# LPC18xx register map
File version: 18
Registers are 32-bit, read-write, reset 0x0 unless marked. A register's access mark holds for its fields unless they carry their own. Offsets are from the block's base; [hi:lo] are bit positions; {n}, {i} and the like mark numbered series.

## EVENTROUTER — Product name title=UM10430 Chapter title=LPC18xx Event router Modification date=1/20/2011 Major revision=0 Minor revision=7
Base 0x40044000
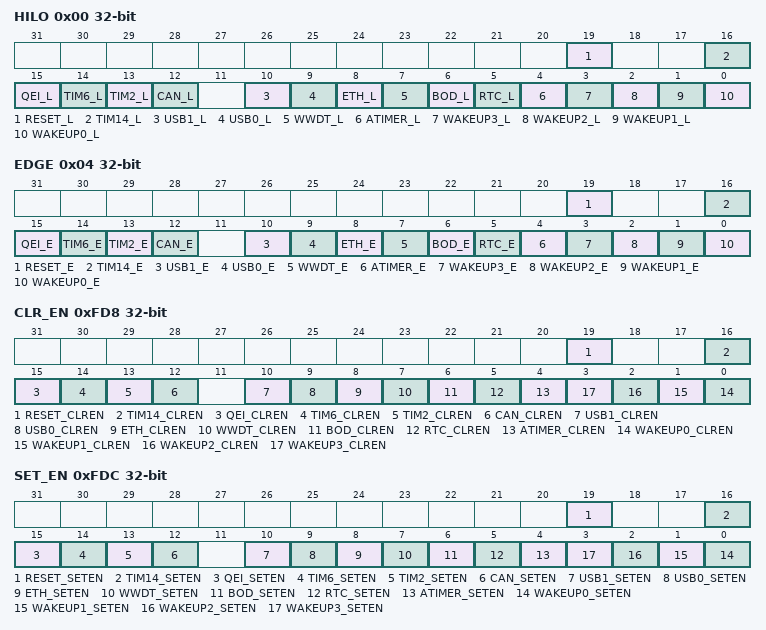
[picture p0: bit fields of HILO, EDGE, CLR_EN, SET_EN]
0x00 HILO — Level configuration register
  [19] RESET_L — Level detect mode for RESET event.
    0=DETECT_LOW_LEVEL_IF_ (Detect LOW level if bit 17 in the EDGE register is 0. Detect falling edge if bit 17 in the EDGE register is 1.); 1=DETECT_HIGH_LEVEL_IF (Detect HIGH level if bit 17 in the EDGE register is 0. Detect rising edge if bit 17 in the EDGE register is 1.)
  [16] TIM14_L — Level detect mode for combined timer output 14 event.
    0=DETECT_LOW_LEVEL_IF_ (Detect LOW level if bit 16 in the EDGE register is 0. Detect falling edge if bit 16 in the EDGE register is 1.); 1=DETECT_HIGH_LEVEL_IF (Detect HIGH level if bit 16 in the EDGE register is 0. Detect rising edge if bit 16 in the EDGE register is 1.)
  [15] QEI_L — Level detect mode for QEI event.
    0=DETECT_LOW_LEVEL_IF_ (Detect LOW level if bit 15 in the EDGE register is 0. Detect falling edge if bit 15 in the EDGE register is 1.); 1=DETECT_HIGH_LEVEL_IF (Detect HIGH level if bit 15 in the EDGE register is 0. Detect rising edge if bit 15 in the EDGE register is 1.)
  [14] TIM6_L — Level detect mode for combined timer output 6 event.
    0=DETECT_LOW_LEVEL_IF_ (Detect LOW level if bit 14 in the EDGE register is 0. Detect falling edge if bit 14 in the EDGE register is 1.); 1=DETECT_HIGH_LEVEL_IF (Detect HIGH level if bit 14 in the EDGE register is 0. Detect rising edge if bit 14 in the EDGE register is 1.)
  [13] TIM2_L — Level detect mode for combined timer output 2 event.
    0=DETECT_LOW_LEVEL_IF_ (Detect LOW level if bit 13 in the EDGE register is 0. Detect falling edge if bit 13 in the EDGE register is 1.); 1=DETECT_HIGH_LEVEL_IF (Detect HIGH level if bit 13 in the EDGE register is 0. Detect rising edge if bit 13 in the EDGE register is 1.)
  [12] CAN_L — Level detect mode for C_CAN event.
    0=DETECT_LOW_LEVEL_IF_ (Detect LOW level if bit 12 in the EDGE register is 0. Detect falling edge if bit 12 in the EDGE register is 1.); 1=DETECT_HIGH_LEVEL_IF (Detect HIGH level if bit 12 in the EDGE register is 0. Detect rising edge if bit 12 in the EDGE register is 1.)
  [10] USB1_L — Level detect mode for USB1 event.
    0=DETECT_LOW_LEVEL_IF_ (Detect LOW level if bit 10 in the EDGE register is 0. Detect falling edge if bit 10 in the EDGE register is 1.); 1=DETECT_HIGH_LEVEL_IF (Detect HIGH level if bit 10 in the EDGE register is 0. Detect rising edge if bit 10 in the EDGE register is 1.)
  [9] USB0_L — Level detect mode for USB0 event.
    0=DETECT_LOW_LEVEL_IF_ (Detect LOW level if bit 9 in the EDGE register is 0. Detect falling edge if bit 9 in the EDGE register is 1.); 1=DETECT_HIGH_LEVEL_IF (Detect HIGH level if bit 9 in the EDGE register is 0. Detect rising edge if bit 9 in the EDGE register is 1.)
  [8] ETH_L — Level detect mode for ethernet event.
    0=DETECT_LOW_LEVEL_IF_ (Detect LOW level if bit 8 in the EDGE register is 0. Detect falling edge if bit 8 in the EDGE register is 1.); 1=DETECT_HIGH_LEVEL_IF (Detect HIGH level if bit 8 in the EDGE register is 0. Detect rising edge if bit 8 in the EDGE register is 1.)
  [7] WWDT_L — Level detect mode for WWDTD event.
    0=DETECT_LOW_LEVEL_IF_ (Detect LOW level if bit 7 in the EDGE register is 0. Detect falling edge if bit 7 in the EDGE register is 1.); 1=DETECT_HIGH_LEVEL_IF (Detect HIGH level if bit 7 in the EDGE register is 0. Detect rising edge if bit 7 in the EDGE register is 1.)
  [6] BOD_L — Level detect mode for BOD event.
    0=DETECT_LOW_LEVEL_IF_ (Detect LOW level if bit 6 in the EDGE register is 0. Detect falling edge if bit 6 in the EDGE register is 1.); 1=DETECT_HIGH_LEVEL_IF (Detect HIGH level if bit 6 in the EDGE register is 0. Detect rising edge if bit 6 in the EDGE register is 1.)
  [5] RTC_L — Level detect mode for RTC event.
    0=DETECT_LOW_LEVEL_IF_ (Detect LOW level if bit 5 in the EDGE register is 0. Detect falling edge if bit 5 in the EDGE register is 1.); 1=DETECT_HIGH_LEVEL_IF (Detect HIGH level if bit 5 in the EDGE register is 0. Detect rising edge if bit 5 in the EDGE register is 1.)
  [4] ATIMER_L — Level detect mode for alarm timer event.
    0=DETECT_LOW_LEVEL_IF_ (Detect LOW level if bit 4 in the EDGE register is 0. Detect falling edge if bit 4 in the EDGE register is 1.); 1=DETECT_HIGH_LEVEL_IF (Detect HIGH level if bit 4 in the EDGE register is 0. Detect rising edge if bit 4 in the EDGE register is 1.)
  [3] WAKEUP3_L — Level detect mode for WAKEUP3 event.
    0=DETECT_LOW_LEVEL_IF_ (Detect LOW level if bit 3 in the EDGE register is 0. Detect falling edge if bit 3 in the EDGE register is 1.); 1=DETECT_HIGH_LEVEL_IF (Detect HIGH level if bit 3 in the EDGE register is 0. Detect rising edge if bit 3 in the EDGE register is 1.)
  [2] WAKEUP2_L — Level detect mode for WAKEUP2 event.
    0=DETECT_LOW_LEVEL_IF_ (Detect LOW level if bit 2 in the EDGE register is 0. Detect falling edge if bit 2 in the EDGE register is 1.); 1=DETECT_HIGH_LEVEL_IF (Detect HIGH level if bit 2 in the EDGE register is 0. Detect rising edge if bit 2 in the EDGE register is 1.)
  [1] WAKEUP1_L — Level detect mode for WAKEUP1 event. The corresponding bit in the EDGE register must be 0.
    0=DETECT_LOW_LEVEL_IF_ (Detect LOW level if bit 1 in the EDGE register is 0.); 1=DETECT_HIGH_LEVEL_IF (Detect HIGH level if bit 1 in the EDGE register is 0. Detect rising edge if bit 1 in the EDGE register is 1.)
  [0] WAKEUP0_L — Level detect mode for WAKEUP0 event.
    0=DETECT_LOW_LEVEL_IF_ (Detect LOW level if bit 0 in the EDGE register is 0. Detect falling edge if bit 0 in the EDGE register is 1.); 1=DETECT_HIGH_LEVEL_IF (Detect HIGH level if bit 0 in the EDGE register is 0. Detect rising edge if bit 0 in the EDGE register is 1.)
0x04 EDGE — Edge configuration
  [19] RESET_E — Edge/level detect mode for RESET event. The corresponding bit in the EDGE register must be 0.
    0=LEVEL_DETECT_; 1=EDGE_DETECT_DETECT_ (Edge detect. Detect falling edge if bit 19 in the HILO register is 0. Detect rising edge if bit 19 in the HILO register is 1.)
  [16] TIM14_E — Edge/level detect mode for combined timer output 14 event. The corresponding bit in the EDGE register must be 0.
    0=LEVEL_DETECT_; 1=EDGE_DETECT_DETECT_ (Edge detect. Detect falling edge if bit 16 in the HILO register is 0. Detect rising edge if bit 16 in the HILO register is 1.)
  [15] QEI_E — Edge/level detect mode for QEI interrupt signal. The corresponding bit in the EDGE register must be 0.
    0=LEVEL_DETECT_; 1=EDGE_DETECT_DETECT_ (Edge detect. Detect falling edge if bit 15 in the HILO register is 0. Detect rising edge if bit 15 in the HILO register is 1.)
  [14] TIM6_E — Edge/level detect mode for combined timer output 6 event. The corresponding bit in the EDGE register must be 0.
    0=LEVEL_DETECT_; 1=EDGE_DETECT_DETECT_ (Edge detect. Detect falling edge if bit 14 in the HILO register is 0. Detect rising edge if bit 14 in the HILO register is 1.)
  [13] TIM2_E — Edge/level detect mode for combined timer output 2 event. The corresponding bit in the EDGE register must be 0.
    0=LEVEL_DETECT_; 1=EDGE_DETECT_DETECT_ (Edge detect. Detect falling edge if bit 13 in the HILO register is 0. Detect rising edge if bit 13 in the HILO register is 1.)
  [12] CAN_E — Edge/level detect mode for C_CAN event. The corresponding bit in the EDGE register must be 0.
    0=LEVEL_DETECT_; 1=EDGE_DETECT_DETECT_ (Edge detect. Detect falling edge if bit 12 in the HILO register is 0. Detect rising edge if bit 12 in the HILO register is 1.)
  [10] USB1_E — Edge/level detect mode for USB1 event. The corresponding bit in the EDGE register must be 0.
    0=LEVEL_DETECT_; 1=EDGE_DETECT_DETECT_ (Edge detect. Detect falling edge if bit 10 in the HILO register is 0. Detect rising edge if bit 10 in the HILO register is 1.)
  [9] USB0_E — Edge/level detect mode for USB0 event. The corresponding bit in the EDGE register must be 0.
    0=LEVEL_DETECT_; 1=EDGE_DETECT_DETECT_ (Edge detect. Detect falling edge if bit 9 in the HILO register is 0. Detect rising edge if bit 9 in the HILO register is 1.)
  [8] ETH_E — Edge/level detect mode for ethernet event. The corresponding bit in the EDGE register must be 0.
    0=LEVEL_DETECT_; 1=EDGE_DETECT_DETECT_ (Edge detect. Detect falling edge if bit 8 in the HILO register is 0. Detect rising edge if bit 8 in the HILO register is 1.)
  [7] WWDT_E — Edge/level detect mode for WWDTD event. The corresponding bit in the EDGE register must be 0.
    0=LEVEL_DETECT_; 1=EDGE_DETECT_DETECT_ (Edge detect. Detect falling edge if bit 7 in the HILO register is 0. Detect rising edge if bit 7 in the HILO register is 1.)
  [6] BOD_E — Edge/level detect mode for BOD event. The corresponding bit in the EDGE register must be 0.
    0=LEVEL_DETECT_; 1=EDGE_DETECT_DETECT_ (Edge detect. Detect falling edge if bit 6 in the HILO register is 0. Detect rising edge if bit 6 in the HILO register is 1.)
  [5] RTC_E — Edge/level detect mode for RTC event. The corresponding bit in the EDGE register must be 0.
    0=LEVEL_DETECT_; 1=EDGE_DETECT_DETECT_ (Edge detect. Detect falling edge if bit 5 in the HILO register is 0. Detect rising edge if bit 5 in the HILO register is 1.)
  [4] ATIMER_E — Edge/level detect mode for alarm timer event. The corresponding bit in the EDGE register must be 0.
    0=LEVEL_DETECT_; 1=EDGE_DETECT_DETECT_ (Edge detect. Detect falling edge if bit 4 in the HILO register is 0. Detect rising edge if bit 4 in the HILO register is 1.)
  [3] WAKEUP3_E — Edge/level detect mode for WAKEUP3 event. The corresponding bit in the EDGE register must be 0.
    0=LEVEL_DETECT_; 1=EDGE_DETECT_DETECT_ (Edge detect. Detect falling edge if bit 30 in the HILO register is 0. Detect rising edge if bit 3 in the HILO register is 1.)
  [2] WAKEUP2_E — Edge/level detect mode for WAKEUP2 event. The corresponding bit in the EDGE register must be 0.
    0=LEVEL_DETECT_; 1=EDGE_DETECT_DETECT_ (Edge detect. Detect falling edge if bit 2 in the HILO register is 0. Detect rising edge if bit 2 in the HILO register is 1.)
  [1] WAKEUP1_E — Edge/level detect mode for WAKEUP1 event. The corresponding bit in the EDGE register must be 0.
    0=LEVEL_DETECT_; 1=EDGE_DETECT_DETECT_ (Edge detect. Detect falling edge if bit 1 in the HILO register is 0. Detect rising edge if bit 1 in the HILO register is 1.)
  [0] WAKEUP0_E — Edge detect mode for WAKEUP0 event.
    0=LEVEL_DETECT_; 1=EDGE_DETECT_DETECT_ (Edge detect. Detect falling edge if bit 0 in the HILO register is 0. Detect rising edge if bit 0 in the HILO register is 1.)
0xFD8 CLR_EN wo — Event clear enable register
  [19] RESET_CLREN — Writing a 1 to this bit clears the event enable bit 19 in the ENABLE register.
  [16] TIM14_CLREN — Writing a 1 to this bit clears the event enable bit 16 in the ENABLE register.
  [15] QEI_CLREN — Writing a 1 to this bit clears the event enable bit 15 in the ENABLE register.
  [14] TIM6_CLREN — Writing a 1 to this bit clears the event enable bit 14 in the ENABLE register.
  [13] TIM2_CLREN — Writing a 1 to this bit clears the event enable bit 13 in the ENABLE register.
  [12] CAN_CLREN — Writing a 1 to this bit clears the event enable bit 12 in the ENABLE register.
  [10] USB1_CLREN — Writing a 1 to this bit clears the event enable bit 10 in the ENABLE register.
  [9] USB0_CLREN — Writing a 1 to this bit clears the event enable bit 9 in the ENABLE register.
  [8] ETH_CLREN — Writing a 1 to this bit clears the event enable bit 8 in the ENABLE register.
  [7] WWDT_CLREN — Writing a 1 to this bit clears the event enable bit 7 in the ENABLE register.
  [6] BOD_CLREN — Writing a 1 to this bit clears the event enable bit 6 in the ENABLE register.
  [5] RTC_CLREN — Writing a 1 to this bit clears the event enable bit 5 in the ENABLE register.
  [4] ATIMER_CLREN — Writing a 1 to this bit clears the event enable bit 4 in the ENABLE register.
  [n] WAKEUP{n}_CLREN (n=0..3) — Writing a 1 to this bit clears the event enable bit {n} in the ENABLE register.
0xFDC SET_EN wo — Event set enable register
  [19] RESET_SETEN — Writing a 1 to this bit sets the event enable bit 19 in the ENABLE register.
  [16] TIM14_SETEN — Writing a 1 to this bit sets the event enable bit 16 in the ENABLE register.
  [15] QEI_SETEN — Writing a 1 to this bit sets the event enable bit 15 in the ENABLE register.
  [14] TIM6_SETEN — Writing a 1 to this bit sets the event enable bit 14 in the ENABLE register.
  [13] TIM2_SETEN — Writing a 1 to this bit sets the event enable bit 13 in the ENABLE register.
  [12] CAN_SETEN — Writing a 1 to this bit sets the event enable bit 12 in the ENABLE register.
  [10] USB1_SETEN — Writing a 1 to this bit sets the event enable bit 10 in the ENABLE register.
  [9] USB0_SETEN — Writing a 1 to this bit sets the event enable bit 9 in the ENABLE register.
  [8] ETH_SETEN — Writing a 1 to this bit sets the event enable bit 8 in the ENABLE register.
  [7] WWDT_SETEN — Writing a 1 to this bit sets the event enable bit 7 in the ENABLE register.
  [6] BOD_SETEN — Writing a 1 to this bit sets the event enable bit 6 in the ENABLE register.
  [5] RTC_SETEN — Writing a 1 to this bit sets the event enable bit 5 in the ENABLE register.
  [4] ATIMER_SETEN — Writing a 1 to this bit sets the event enable bit 4 in the ENABLE register.
  [n] WAKEUP{n}_SETEN (n=0..3) — Writing a 1 to this bit sets the event enable bit {n} in the ENABLE register.
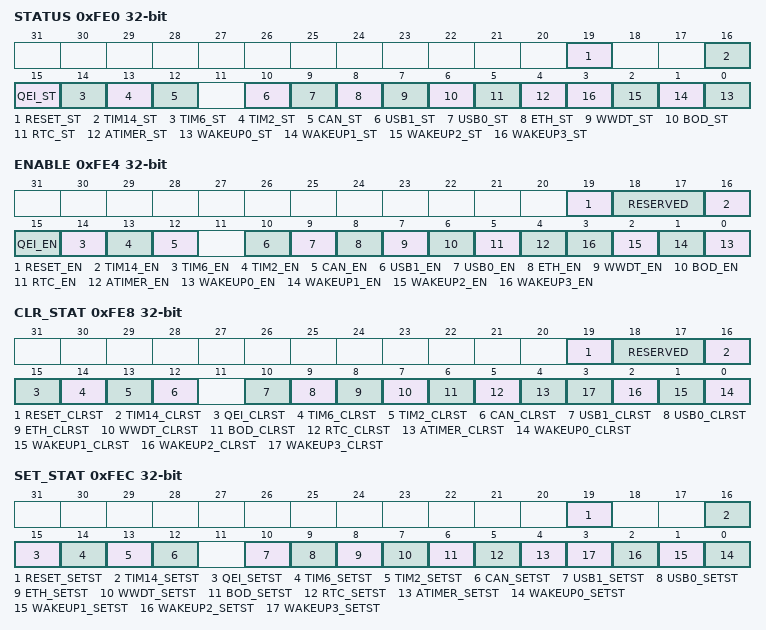
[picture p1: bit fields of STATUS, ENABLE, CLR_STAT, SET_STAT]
0xFE0 STATUS ro
  [19] RESET_ST — A 1 in this bit shows that the event has been raised.
  [16] TIM14_ST — A 1 in this bit shows that the combined timer 14 output event has been raised.
  [15] QEI_ST — A 1 in this bit shows that the QEI event has been raised.
  [14] TIM6_ST — A 1 in this bit shows that the combined timer 6 output event has been raised.
  [13] TIM2_ST — A 1 in this bit shows that the combined timer 2 output event has been raised.
  [12] CAN_ST — A 1 in this bit shows that the C_CAN event has been raised.
  [10] USB1_ST — A 1 in this bit shows that the USB1 event has been raised.
  [9] USB0_ST — A 1 in this bit shows that the USB0 event has been raised.
  [8] ETH_ST — A 1 in this bit shows that the ETHERNET event has been raised.
  [7] WWDT_ST — A 1 in this bit shows that the WWDT event has been raised.
  [6] BOD_ST — A 1 in this bit shows that the BOD event has been raised.
  [5] RTC_ST — A 1 in this bit shows that the RTC event has been raised.
  [4] ATIMER_ST — A 1 in this bit shows that the ATIMER event has been raised.
  [n] WAKEUP{n}_ST (n=0..3) — A 1 in this bit shows that the WAKEUP{n} event has been raised.
0xFE4 ENABLE ro
  [19] RESET_EN — A 1 in this bit shows that the RESET event has been enabled. This event wakes up the chip and contributes to the event router interrupt when bit 0 = 1 in the STATUS register.
  [18:17] RESERVED
  [16] TIM14_EN — A 1 in this bit shows that the TIM14 event has been enabled. This event wakes up the chip and contributes to the event router interrupt when bit 0 = 1 in the STATUS register.
  [15] QEI_EN — A 1 in this bit shows that the QEI event has been enabled. This event wakes up the chip and contributes to the event router interrupt when bit 0 = 1 in the STATUS register.
  [14] TIM6_EN — A 1 in this bit shows that the TIM6 event has been enabled. This event wakes up the chip and contributes to the event router interrupt when bit 0 = 1 in the STATUS register.
  [13] TIM2_EN — A 1 in this bit shows that the TIM2 event has been enabled. This event wakes up the chip and contributes to the event router interrupt when bit 0 = 1 in the STATUS register.
  [12] CAN_EN — A 1 in this bit shows that the CAN event has been enabled. This event wakes up the chip and contributes to the event router interrupt when bit 0 = 1 in the STATUS register.
  [10] USB1_EN — A 1 in this bit shows that the USB1 event has been enabled. This event wakes up the chip and contributes to the event router interrupt when bit 0 = 1 in the STATUS register.
  [9] USB0_EN — A 1 in this bit shows that the USB0 event has been enabled. This event wakes up the chip and contributes to the event router interrupt when bit 0 = 1 in the STATUS register.
  [8] ETH_EN — A 1 in this bit shows that the ETHERNET event has been enabled. This event wakes up the chip and contributes to the event router interrupt when bit 0 = 1 in the STATUS register.
  [7] WWDT_EN — A 1 in this bit shows that the WWDT event has been enabled. This event wakes up the chip and contributes to the event router interrupt when bit 0 = 1 in the STATUS register.
  [6] BOD_EN — A 1 in this bit shows that the BOD event has been enabled. This event wakes up the chip and contributes to the event router interrupt when bit 0 = 1 in the STATUS register.
  [5] RTC_EN — A 1 in this bit shows that the RTC event has been enabled. This event wakes up the chip and contributes to the event router interrupt when bit 0 = 1 in the STATUS register.
  [4] ATIMER_EN — A 1 in this bit shows that the ATIMER event has been enabled. This event wakes up the chip and contributes to the event router interrupt when bit 0 = 1 in the STATUS register.
  [n] WAKEUP{n}_EN (n=0..3) — A 1 in this bit shows that the WAKEUP{n} event has been enabled. This event wakes up the chip and contributes to the event router interrupt when bit 0 = 1 in the STATUS register.
0xFE8 CLR_STAT wo — Clear register
  [19] RESET_CLRST — Writing a 1 to this bit clears the STATUS event bit 19 in the STATUS register.
  [18:17] RESERVED
  [16] TIM14_CLRST — Writing a 1 to this bit clears the STATUS event bit 16 in the STATUS register.
  [15] QEI_CLRST — Writing a 1 to this bit clears the STATUS event bit 15 in the STATUS register.
  [14] TIM6_CLRST — Writing a 1 to this bit clears the STATUS event bit 14 in the STATUS register.
  [13] TIM2_CLRST — Writing a 1 to this bit clears the STATUS event bit 13 in the STATUS register.
  [12] CAN_CLRST — Writing a 1 to this bit clears the STATUS event bit 12 in the STATUS register.
  [10] USB1_CLRST — Writing a 1 to this bit clears the STATUS event bit 10 in the STATUS register.
  [9] USB0_CLRST — Writing a 1 to this bit clears the STATUS event bit 9 in the STATUS register.
  [8] ETH_CLRST — Writing a 1 to this bit clears the STATUS event bit 8 in the STATUS register.
  [7] WWDT_CLRST — Writing a 1 to this bit clears the STATUS event bit 7 in the STATUS register.
  [6] BOD_CLRST — Writing a 1 to this bit clears the STATUS event bit 6 in the STATUS register.
  [5] RTC_CLRST — Writing a 1 to this bit clears the STATUS event bit 5 in the STATUS register.
  [4] ATIMER_CLRST — Writing a 1 to this bit clears the STATUS event bit 4 in the STATUS register.
  [n] WAKEUP{n}_CLRST (n=0..3) — Writing a 1 to this bit clears the STATUS event bit {n} in the STATUS register.
0xFEC SET_STAT wo — Set register
  [19] RESET_SETST — Writing a 1 to this bit sets the STATUS event bit 19 in the STATUS register.
  [16] TIM14_SETST — Writing a 1 to this bit sets the STATUS event bit 16 in the STATUS register.
  [15] QEI_SETST — Writing a 1 to this bit sets the STATUS event bit 15 in the STATUS register.
  [14] TIM6_SETST — Writing a 1 to this bit sets the STATUS event bit 14 in the STATUS register.
  [13] TIM2_SETST — Writing a 1 to this bit sets the STATUS event bit 13 in the STATUS register.
  [12] CAN_SETST — Writing a 1 to this bit sets the STATUS event bit 12 in the STATUS register.
  [10] USB1_SETST — Writing a 1 to this bit sets the STATUS event bit 10 in the STATUS register.
  [9] USB0_SETST — Writing a 1 to this bit sets the STATUS event bit 9 in the STATUS register.
  [8] ETH_SETST — Writing a 1 to this bit sets the STATUS event bit 8 in the STATUS register.
  [7] WWDT_SETST — Writing a 1 to this bit sets the STATUS event bit 7 in the STATUS register.
  [6] BOD_SETST — Writing a 1 to this bit sets the STATUS event bit 6 in the STATUS register.
  [5] RTC_SETST — Writing a 1 to this bit sets the STATUS event bit 5 in the STATUS register.
  [4] ATIMER_SETST — Writing a 1 to this bit sets the STATUS event bit 4 in the STATUS register.
  [n] WAKEUP{n}_SETST (n=0..3) — Writing a 1 to this bit sets the STATUS event bit {n} in the STATUS register.
